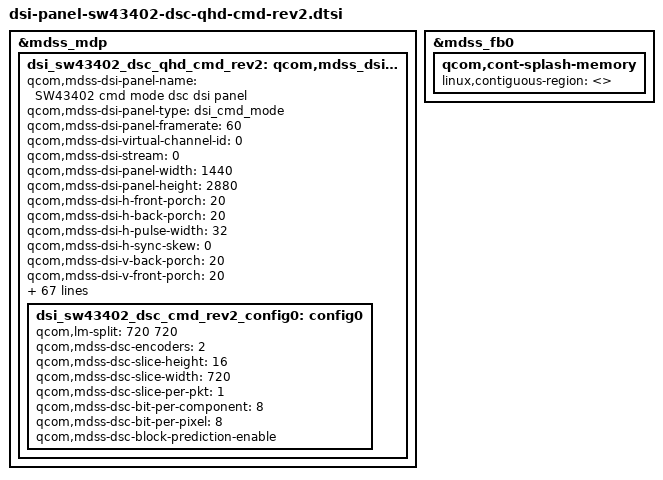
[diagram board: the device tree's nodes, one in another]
/* Copyright (c) 2017, LGE Inc. All rights reserved.
 *
 * This program is free software; you can redistribute it and/or modify
 * it under the terms of the GNU General Public License version 2 and
 * only version 2 as published by the Free Software Foundation.
 *
 * This program is distributed in the hope that it will be useful,
 * but WITHOUT ANY WARRANTY; without even the implied warranty of
 * MERCHANTABILITY or FITNESS FOR A PARTICULAR PURPOSE.  See the
 * GNU General Public License for more details.
 */

&mdss_mdp {
	dsi_sw43402_dsc_qhd_cmd_rev2: qcom,mdss_dsi_sw43402_dsc_qhd_cmd_rev2 {
		qcom,mdss-dsi-panel-name =
					"SW43402 cmd mode dsc dsi panel";
		qcom,mdss-dsi-panel-type = "dsi_cmd_mode";
		qcom,mdss-dsi-panel-framerate = <60>;
		qcom,mdss-dsi-virtual-channel-id = <0>;
		qcom,mdss-dsi-stream = <0>;
		qcom,mdss-dsi-panel-width = <1440>;
		qcom,mdss-dsi-panel-height = <2880>;
		qcom,mdss-dsi-h-front-porch = <20>;
		qcom,mdss-dsi-h-back-porch = <20>;
		qcom,mdss-dsi-h-pulse-width = <32>;
		qcom,mdss-dsi-h-sync-skew = <0>;
		qcom,mdss-dsi-v-back-porch = <20>;
		qcom,mdss-dsi-v-front-porch = <20>;
		qcom,mdss-dsi-v-pulse-width = <4>;
		qcom,mdss-dsi-h-left-border = <0>;
		qcom,mdss-dsi-h-right-border = <0>;
		qcom,mdss-dsi-v-top-border = <0>;
		qcom,mdss-dsi-v-bottom-border = <0>;
		qcom,mdss-dsi-bpp = <24>;
		qcom,mdss-dsi-color-order = "rgb_swap_rgb";
		qcom,mdss-dsi-underflow-color = <0xff>;
		qcom,mdss-dsi-border-color = <0>;
		qcom,mdss-dsi-h-sync-pulse = <0>;
		qcom,mdss-dsi-traffic-mode = "burst_mode";
		qcom,mdss-dsi-lane-map = "lane_map_0123";
		qcom,mdss-dsi-bllp-eof-power-mode;
		qcom,mdss-dsi-bllp-power-mode;
		qcom,mdss-dsi-lane-0-state;
		qcom,mdss-dsi-lane-1-state;
		qcom,mdss-dsi-lane-2-state;
		qcom,mdss-dsi-lane-3-state;
		qcom,mdss-dsi-reset-sequence = <1 10>, <0 10>, <1 10>;
		qcom,mdss-dsi-dma-trigger = "trigger_sw";
		qcom,mdss-dsi-mdp-trigger = "none";
		qcom,mdss-dsi-te-pin-select = <1>;
		qcom,mdss-dsi-wr-mem-start = <0x2c>;
		qcom,mdss-dsi-wr-mem-continue = <0x3c>;
		qcom,mdss-dsi-te-dcs-command = <1>;
		qcom,mdss-dsi-te-check-enable;
		qcom,mdss-dsi-te-using-te-pin;
		qcom,mdss-dsi-lp11-init;
		qcom,mdss-dsi-tx-eot-append;
		qcom,mdss-mdp-transfer-time-us = <15000>;
		qcom,ulps-enabled;
		qcom,err-detect-enabled = <1>;

		qcom,mdss-dsi-on-command = [
			39 01 00 00 00 00 03 B0
			20 43
			39 01 00 00 00 00 03 DF
			0A 70
			39 01 00 00 00 00 03 B0
			A5 00
			39 01 00 00 00 00 0D B2
			5D 01 02 80 00 FF
			FF 15 00 00 00 00
			05 01 00 00 00 00 01 35
			05 01 00 00 3C 00 01 11
			15 01 00 00 00 00 02 53
			00
			15 01 00 00 00 00 02 55
			0C
			39 01 00 00 00 00 03 FB
			03 77
			39 01 00 00 00 00 06 ED
			13 00 06 00 00
			39 01 00 00 14 00 0F E2
			20 0D 08 A8 0A AA
			04 44 80 80 80 5C
			5C 5C
		];

		qcom,mdss-dsi-post-panel-on-command = [
			05 01 00 00 00 00 01 29
		];

		qcom,mdss-dsi-on-command-state = "dsi_lp_mode";

		qcom,mdss-dsi-off-command = [
			39 01 00 00 00 00 05 E8
			08 90 18 05
			05 01 00 00 00 00 01 28
			05 01 00 00 64 00 01 10
		];
		qcom,mdss-dsi-off-command-state = "dsi_lp_mode";
		qcom,mdss-dsi-lp-mode-on = [
			15 01 00 00 00 00 02 53
			08
			39 01 00 00 00 00 08 CA
			00 46 00 46 00 16 11
			39 01 00 00 00 00 0F E6
			45 C5 04 88 D3 00 0A
			0B 00 0A 0B 00 05 0B
			];
		qcom,mdss-dsi-lp-mode-off = [
			15 01 00 00 00 00 02 53
			00
			39 01 00 00 00 00 08 CA
			00 46 00 46 00 16 10
			39 01 00 00 00 00 0F E6
			45 C5 04 88 D1 00 0A
			0B 00 0A 0B 00 05 0B
			];
		qcom,mdss-dsi-lp-change-state = "dsi_hs_mode";
		qcom,mode-control-dsi-state = "dsi_lp_mode";

		qcom,alpm-off-command = [
			15 01 00 00 00 00 02 5E 00
			15 01 00 00 00 00 02 51 00
			05 01 00 00 12 00 01 22
			05 01 00 00 00 00 01 38
			39 01 00 00 00 00 03 E2 20 0D
			05 01 00 00 40 00 01 28
			05 01 00 00 00 00 01 13
			05 01 00 00 00 00 01 29
		];
		qcom,alpm-dim-command = [
			05 01 00 00 00 00 01 22
			15 01 00 00 00 00 02 E0 1A
			39 01 00 00 34 00 03 E2 20 03
			39 01 00 00 00 00 03 E4 30 44
			39 01 00 00 00 00 07 E5 04 06 03 03 56 61
			39 01 00 00 00 00 09 E7 00 0D 76 23 00 00 0D 44
			05 01 00 00 00 00 01 39
			15 01 00 00 00 00 02 51 4A
			05 01 00 00 54 00 01 13
			15 01 00 00 00 00 02 5E 10
		];
		qcom,alpm-low-command = [
			05 01 00 00 00 00 01 22
			15 01 00 00 00 00 02 E0 1A
			39 01 00 00 34 00 03 E2 20 03
			39 01 00 00 00 00 03 E4 30 44
			39 01 00 00 00 00 07 E5 04 06 03 03 56 61
			39 01 00 00 00 00 09 E7 00 0D 76 23 00 00 0D 44
			05 01 00 00 00 00 01 39
			15 01 00 00 00 00 02 51 70
			05 01 00 00 54 00 01 13
			15 01 00 00 00 00 02 5E 10
		];
		qcom,alpm-high-command = [
			05 01 00 00 00 00 01 22
			15 01 00 00 00 00 02 E0 1A
			39 01 00 00 34 00 03 E2 20 03
			39 01 00 00 00 00 03 E4 30 04
			39 01 00 00 00 00 07 E5 04 06 03 03 56 61
			39 01 00 00 00 00 09 E7 00 0D 76 23 00 00 0D 44
			05 01 00 00 00 00 01 39
			15 01 00 00 00 00 02 51 BA
			05 01 00 00 54 00 01 13
			15 01 00 00 00 00 02 5E 10
		];
		qcom,alpm-dim-transition-command = [
			15 01 00 00 00 00 02 51 4A
			39 01 00 00 20 00 03 E4 30 44
		];
		qcom,alpm-low-transition-command = [
			15 01 00 00 00 00 02 51 70
			39 01 00 00 20 00 03 E4 30 44
		];
		qcom,alpm-high-transition-command = [
			15 01 00 00 00 00 02 51 BA
			39 01 00 00 20 00 03 E4 30 04
		];
		qcom,mdss-pan-physical-width-dimension = <68>;
		qcom,mdss-pan-physical-height-dimension = <136>;

		qcom,compression-mode = "dsc";
		qcom,config-select = <&dsi_sw43402_dsc_cmd_rev2_config0>;

		qcom,mdss-dsc-version = <0x11>;
		qcom,mdss-dsc-scr-version = <0x1>;

		dsi_sw43402_dsc_cmd_rev2_config0: config0 {
			qcom,lm-split = <720 720>;
			qcom,mdss-dsc-encoders = <2>;
			qcom,mdss-dsc-slice-height = <16>;
			qcom,mdss-dsc-slice-width = <720>;
			qcom,mdss-dsc-slice-per-pkt = <1>;

			qcom,mdss-dsc-bit-per-component = <8>;
			qcom,mdss-dsc-bit-per-pixel = <8>;
			qcom,mdss-dsc-block-prediction-enable;
		};
	};
};

&mdss_fb0 {
	qcom,cont-splash-memory {
		linux,contiguous-region = <>;
	};
};
